# PIC32CX5109BZ36032_SL3 register map
Vendor: Microchip Technology; Series: PIC32CXBZ36; File version: 0
CPU: CM4 r0p1, little endian, MPU, FPU, 3 interrupt priority bits, 43 interrupts
Registers are 32-bit, read-write, reset 0x0 unless marked. A register's access mark holds for its fields unless they carry their own. Offsets are from the block's base; [hi:lo] are bit positions; {n}, {i} and the like mark numbered series.

## CMCC — Cortex M Cache Controller
Base 0x41002000
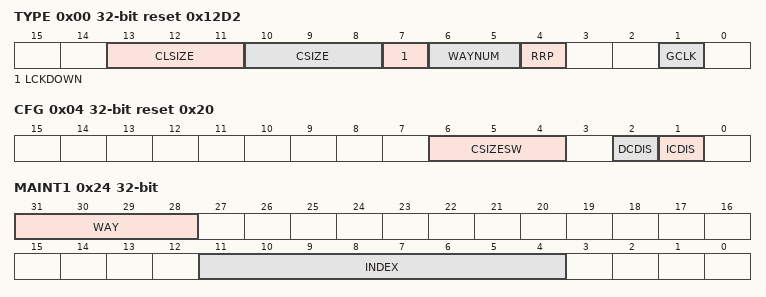
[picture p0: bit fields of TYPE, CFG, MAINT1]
0x00 TYPE ro reset 0x12D2 — Cache Type Register
  [13:11] CLSIZE — Cache Line Size
    0=CLSIZE_4B (Cache Line Size is 4 bytes); 1=CLSIZE_8B (Cache Line Size is 8 bytes); 2=CLSIZE_16B (Cache Line Size is 16 bytes); 3=CLSIZE_32B (Cache Line Size is 32 bytes); 4=CLSIZE_64B (Cache Line Size is 64 bytes); 5=CLSIZE_128B (Cache Line Size is 128 bytes)
  [10:8] CSIZE — Cache Size
    0=CSIZE_1KB (Cache Size is 1 KB); 1=CSIZE_2KB (Cache Size is 2 KB); 2=CSIZE_4KB (Cache Size is 4 KB); 3=CSIZE_8KB (Cache Size is 8 KB); 4=CSIZE_16KB (Cache Size is 16 KB); 5=CSIZE_32KB (Cache Size is 32 KB); 6=CSIZE_64KB (Cache Size is 64 KB)
  [7] LCKDOWN — Lock Down supported
  [6:5] WAYNUM — Number of Way
    0=DMAPPED (Direct Mapped Cache); 1=ARCH2WAY (2-WAY set associative); 2=ARCH4WAY (4-WAY set associative)
  [4] RRP — Round Robin Policy supported
  [1] GCLK — dynamic Clock Gating supported
0x04 CFG reset 0x20 — Cache Configuration Register
  [6:4] CSIZESW — Cache size configured by software
    0=CONF_CSIZE_1KB (The Cache Size is configured to 1KB); 1=CONF_CSIZE_2KB (The Cache Size is configured to 2KB); 2=CONF_CSIZE_4KB (The Cache Size is configured to 4KB); 3=CONF_CSIZE_8KB (The Cache Size is configured to 8KB); 4=CONF_CSIZE_16KB (The Cache Size is configured to 16KB); 5=CONF_CSIZE_32KB (The Cache Size is configured to 32KB); 6=CONF_CSIZE_64KB (The Cache Size is configured to 64KB)
  [2] DCDIS — Data Cache Disable
  [1] ICDIS — Instruction Cache Disable
0x08 CTRL wo — Cache Control Register
  [0] CEN — Cache Controller Enable
0x0C SR ro — Cache Status Register
  [0] CSTS — Cache Controller Status
0x10 LCKWAY — Cache Lock per Way Register
  [3:0] LCKWAY — Lockdown way Register
0x20 MAINT0 wo — Cache Maintenance Register 0
  [0] INVALL — Cache Controller invalidate All
0x24 MAINT1 wo — Cache Maintenance Register 1
  [31:28] WAY — Invalidate Way
    {v}=Way {v} is selection for index invalidation (v=0..3)
  [11:4] INDEX — Invalidate Index
0x28 MCFG — Cache Monitor Configuration Register
  [1:0] MODE — Cache Controller Monitor Counter Mode
    0=CYCLE_COUNT (Cycle counter); 1=IHIT_COUNT (Instruction hit counter); 2=DHIT_COUNT (Data hit counter)
0x2C MEN — Cache Monitor Enable Register
  [0] MENABLE — Cache Controller Monitor Enable
0x30 MCTRL wo — Cache Monitor Control Register
  [0] SWRST — Cache Controller Software Reset
0x34 MSR ro — Cache Monitor Status Register
  [31:0] EVENT_CNT — Monitor Event Counter

## CoreDebug
Base 0xE000EDF0
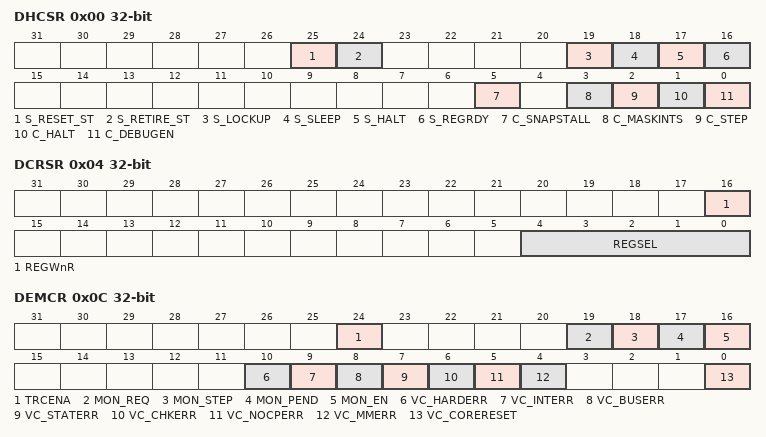
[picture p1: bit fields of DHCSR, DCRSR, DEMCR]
0x00 DHCSR — Debug Halting Control and Status Register
  [25] S_RESET_ST, [24] S_RETIRE_ST, [19] S_LOCKUP, [18] S_SLEEP, [17] S_HALT, [16] S_REGRDY, [5] C_SNAPSTALL, [3] C_MASKINTS, [2] C_STEP, [1] C_HALT, [0] C_DEBUGEN
0x04 DCRSR wo — Debug Core Register Selector Register
  [16] REGWnR, [4:0] REGSEL
0x08 DCRDR — Debug Core Register Data Register
0x0C DEMCR — Debug Exception and Monitor Control Register
  [24] TRCENA, [19] MON_REQ, [18] MON_STEP, [17] MON_PEND, [16] MON_EN, [10] VC_HARDERR, [9] VC_INTERR, [8] VC_BUSERR, [7] VC_STATERR, [6] VC_CHKERR, [5] VC_NOCPERR, [4] VC_MMERR, [0] VC_CORERESET

## DAC_CTRL — Descriptive Title of Macro
Base 0x44003C00
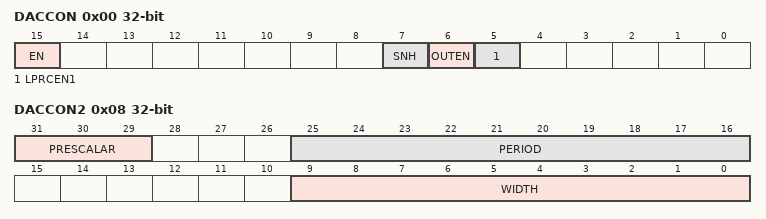
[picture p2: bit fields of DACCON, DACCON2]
0x00 DACCON — CONTROL Register
  [15] EN — Enable
    0=DAC_DISABLE (The peripheral is disabled.); 1=DAC_ENABLE (The peripheral is enabled.)
  [7] SNH — Sample and hold circuitry
    0=SNH_NORMAL (DAC operation in normal mode); 1=SNH_LOWPOWER (DAC operation in low power mode)
  [6] OUTEN — Will enable the output buffer
    0=OUTEN_DISABLE (Output buffer disabled); 1=OUTEN_ENABLE (Output buffer enabled)
  [5] LPRCEN1 — LPRC clock enabled for SnH mode
    0=LPRC_ENABLE (LPRC clock not enabled); 1=LPRC_DISABLE (LPRC clock enabled)
0x04 DACCODE
  [6:0] DATA — DAC data
0x08 DACCON2 — DAC Config register1
  [31:29] PRESCALAR — Prescaling factor for SnH clock
  [25:16] PERIOD — SnH clock period
  [9:0] WIDTH — SnH clock width

## Notices in the file
Copyright (c) 2026 Microchip Technology Inc.
SPDX-License-Identifier: Apache-2.0
Licensed under the Apache License, Version 2.0 (the "License");
you may not use this file except in compliance with the License.
You may obtain a copy of the License at
http://www.apache.org/licenses/LICENSE-2.0
Unless required by applicable law or agreed to in writing, software
distributed under the License is distributed on an "AS IS" BASIS,
WITHOUT WARRANTIES OR CONDITIONS OF ANY KIND, either express or implied.
See the License for the specific language governing permissions and
limitations under the License.
